# Montana register map
Vendor: ONSemiconductor; Series: Montana Series; File version: 1.0
CPU: CM33 r0p4, little endian, MPU, FPU, 3 interrupt priority bits
Registers are 32-bit, read-write, reset 0x0 unless marked. A register's access mark holds for its fields unless they carry their own. Offsets are from the block's base; [hi:lo] are bit positions; {n}, {i} and the like mark numbered series.

## SENSOR — Sensor domain (Analog Bridge Access)
Base 0x40001700
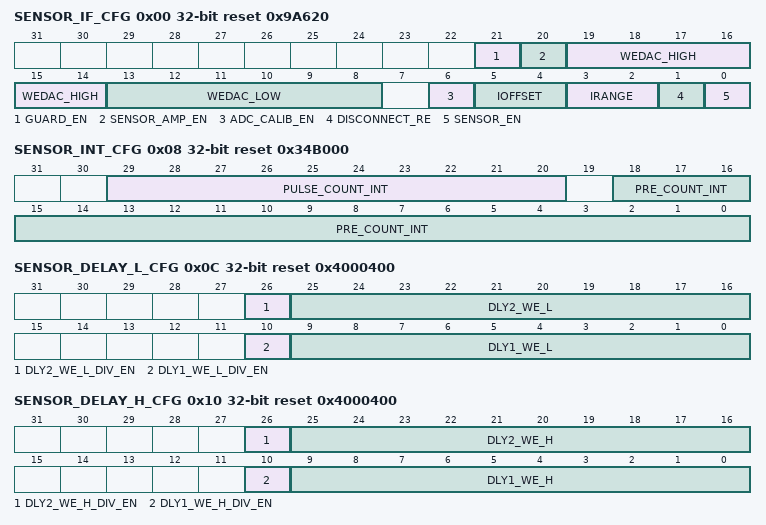
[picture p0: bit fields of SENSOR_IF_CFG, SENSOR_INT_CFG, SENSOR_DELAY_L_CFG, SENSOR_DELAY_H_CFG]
0x00 SENSOR_IF_CFG reset 0x9A620 — Sensor ADC configuration register
  [21] GUARD_EN — Guard buffer enable
    0=SENSOR_GUARD_DISABLED (Guard buffer disabled); 1=SENSOR_GUARD_ENABLED (Guard buffer enabled)
  [20] SENSOR_AMP_EN — Sensor amplifier enable
    0=SENSOR_AMP_DISABLED (Sensor amplifier disabled); 1=SENSOR_AMP_ENABLED (Sensor amplifier enabled)
  [19:14] WEDAC_HIGH — WEDAC output voltage during WE pulse
    0=SENSOR_WEDAC_HIGH_0000 (WEDAC_HIGH = 0.000V); 1=SENSOR_WEDAC_HIGH_0016 (WEDAC_HIGH = 0.016V); 2=SENSOR_WEDAC_HIGH_0032 (WEDAC_HIGH = 0.032V); 31=SENSOR_WEDAC_HIGH_0496 (WEDAC_HIGH = 0.496V); 32=SENSOR_WEDAC_HIGH_0504 (WEDAC_HIGH = 0.504V); 38=SENSOR_WEDAC_HIGH_0600 (WEDAC_HIGH = 0.600V); 39=SENSOR_WEDAC_HIGH_0616 (WEDAC_HIGH = 0.616V); 62=SENSOR_WEDAC_HIGH_0984 (WEDAC_HIGH = 0.984V); 63=SENSOR_WEDAC_HIGH_1000 (WEDAC_HIGH = 1.000V)
  [13:8] WEDAC_LOW — WEDAC output voltage except during WE pulse
    0=SENSOR_WEDAC_LOW_0000 (WEDAC_LOW = 0.000V); 1=SENSOR_WEDAC_LOW_0016 (WEDAC_LOW = 0.016V); 2=SENSOR_WEDAC_LOW_0032 (WEDAC_LOW = 0.032V); 31=SENSOR_WEDAC_LOW_0496 (WEDAC_LOW = 0.496V); 32=SENSOR_WEDAC_LOW_0504 (WEDAC_LOW = 0.504V); 38=SENSOR_WEDAC_LOW_0600 (WEDAC_LOW = 0.600V); 39=SENSOR_WEDAC_LOW_0616 (WEDAC_LOW = 0.616V); 62=SENSOR_WEDAC_LOW_0984 (WEDAC_LOW = 0.984V); 63=SENSOR_WEDAC_LOW_1000 (WEDAC_LOW = 1.000V)
  [6] ADC_CALIB_EN — ADC calibration mode enable (switches S2 & S3)
    0=SENSOR_CALIB_DISABLED (ADC calibration disabled); 1=SENSOR_CALIB_ENABLED (ADC calibration enabled)
  [5:4] IOFFSET — Sensor interface offset current setting
    0=SENSOR_IOFFSET_0NA (0 nA); 1=SENSOR_IOFFSET_10NA (10 nA); 2=SENSOR_IOFFSET_20NA (20 nA); 3=SENSOR_IOFFSET_40NA (40 nA)
  [3:2] IRANGE — Sensor interface measurement range
    0=SENSOR_IRANGE_50NA (50 nA); 1=SENSOR_IRANGE_80NA (80 nA); 2=SENSOR_IRANGE_170NA (170 nA); 3=SENSOR_IRANGE_240NA (240 nA)
  [1] DISCONNECT_RE — RE ground switch control (switch S1)
    0=SENSOR_RE_VSSA (RE shorted to VSSA); 1=SENSOR_RE_HIGHZ (RE high-Z)
  [0] SENSOR_EN — Sensor interface enable
    0=SENSOR_DISABLED (Sensor interface disabled); 1=SENSOR_ENABLED (Sensor interface enabled)
0x04 SENSOR_CLK_CFG — Sensor clock configuration register
  [0] CLK_SEL — Clock source selection
    0=SENSOR_CLK_RTC (RTC timer clock is used as sensor clock); 1=SENSOR_CLK_SLOWCLK (Divided SLOWCLK is used as sensor clock)
0x08 SENSOR_INT_CFG reset 0x34B000 — Sensor Integration Time Values
  [29:20] PULSE_COUNT_INT — Duration of "Pulse Count Sample" state
    {v}=Number of periods for "Pulse Count Sample State": {v+1} (v=0..3); 255=Number of periods for "Pulse Count Sample State": 256; 0x3FF=Number of periods for "Pulse Count Sample State": 1024
  [18:0] PRE_COUNT_INT — Absolute Value of main counter to trigger the change of "Pre Count Sample" state
    0=Number of periods for "Pre Count Int State": 1; 1=Number of periods for "Pre Count Int State": 2; 0x4AFFF=Number of periods for "Pre Count Int State": 307199; 0x4B000=Number of periods for "Pre Count Int State": 307200; 0x7FFFF=Number of periods for "Pre Count Int State": 2**19
0x0C SENSOR_DELAY_L_CFG reset 0x4000400 — Sensor Delays Time Values for Low states
  [26] DLY2_WE_L_DIV_EN
    0=DLY2_WE_L_DIV_DISABLED (Delay 2 WE_L runs at 32 kHz); 1=DLY2_WE_L_DIV_ENABLED (Delay 2 WE_L runs at 1 kHz)
  [25:16] DLY2_WE_L — Absolute Value of main counter to trigger the change of "Delay 2 WE_L" state
    0=Number of periods for "Delay 2 WE_L": 1; 1=Number of periods for "Delay 2 WE_L": 2; 255=Number of periods for "Delay 2 WE_L": 256; 0x3FF=Number of periods for "Delay 2 WE_L": 1024
  [10] DLY1_WE_L_DIV_EN
    0=DLY1_WE_L_DIV_DISABLED (Delay 1 WE_L runs at 32 kHz); 1=DLY1_WE_L_DIV_ENABLED (Delay 1 WE_L runs at 1 kHz)
  [9:0] DLY1_WE_L — Absolute Value of main counter to trigger the change of "Delay 1 WE_L" state
    0=Number of periods for "Delay 1 WE_L": 1; 1=Number of periods for "Delay 1 WE_L": 2; 255=Number of periods for "Delay 1 WE_L": 256; 0x3FF=Number of periods for "Delay 1 WE_L": 1024
0x10 SENSOR_DELAY_H_CFG reset 0x4000400 — Sensor Delays Time Values for High states
  [26] DLY2_WE_H_DIV_EN
    0=DLY2_WE_H_DIV_DISABLED (Delay 2 WE_H runs at 32 kHz); 1=DLY2_WE_H_DIV_ENABLED (Delay 2 WE_H runs at 1 kHz)
  [25:16] DLY2_WE_H — Absolute Value of main counter to trigger the change of "Delay 2 WE_H" state
    0=Number of periods for "Delay 2 WE_H": 1; 1=Number of periods for "Delay 2 WE_H": 2; 255=Number of periods for "Delay 2 WE_H": 256; 0x3FF=Number of periods for "Delay 2 WE_H": 1024
  [10] DLY1_WE_H_DIV_EN
    0=DLY1_WE_H_DIV_DISABLED (Delay 1 WE_H runs at 32 kHz); 1=DLY1_WE_H_DIV_ENABLED (Delay 1 WE_H runs at 1 kHz)
  [9:0] DLY1_WE_H — Absolute Value of main counter to trigger the change of "Delay 1 WE_H" state
    0=Number of periods for "Delay 1 WE_H": 1; 1=Number of periods for "Delay 1 WE_H": 2; 255=Number of periods for "Delay 1 WE_H": 256; 0x3FF=Number of periods for "Delay 1 WE_H": 1024
0x14 SENSOR_IDLE_CFG reset 0x4B000 — Sensor Idle Time Values
  [18:0] IDLE_TIME — Absolute Value of main counter to trigger the change of "Idle Time" state
    0=Number of periods for: 1; 1=Number of periods for: 2; 0x4B000=Number of periods for: 307200; 0x7FFFF=Number of periods for: 2**19
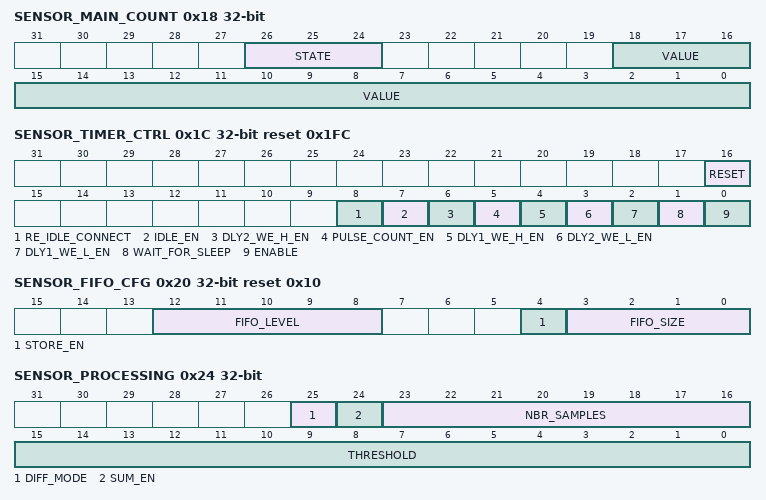
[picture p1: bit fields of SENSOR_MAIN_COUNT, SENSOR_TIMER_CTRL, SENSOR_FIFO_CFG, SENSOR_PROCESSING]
0x18 SENSOR_MAIN_COUNT ro — Sensor Main Counter Current Value
  [26:24] STATE — Sensor timer state
    0=DELAY_1_L_STATUS (Sensor Timer is on Delay 1 L state); 1=PRE_COUNT_STATUS (Sensor Timer is on Pre Count state); 2=DELAY_2_L_STATUS (Sensor Timer is on Delay 2 L state); 3=DELAY_1_H_STATUS (Sensor Timer is on Delay 1 H state); 4=PULSE_COUNT_STATUS (Sensor Timer is on Pulse Count state); 5=DELAY_2_H_STATUS (Sensor Timer is on Delay 2 H state); 6=IDLE_STATUS (Sensor Timer is on Idle state)
  [18:0] VALUE — Sensor main counter current value
0x1C SENSOR_TIMER_CTRL reset 0x1FC (reset mask 0x1FF) — Sensor Timer Control Register
  [16] RESET wo — Reset the Sensor timer
    1=SENSOR_CNT_RESET (The sensor timer counter, the sensor timer enable and the ADC counter are reset)
  [8] RE_IDLE_CONNECT — During idle state connect or disconnect RE pad
    0=RE_DISCONNECTED (The RE pad is disconnected during idle state); 1=RE_CONNECTED (The RE pad is connected during idle state)
  [7] IDLE_EN — Idle state enable
    0=IDLE_NOT_USED (Idle state is not used); 1=IDLE_USED (Idle state is used)
  [6] DLY2_WE_H_EN — Delay 2 WE_H state enable
    0=DLY2_WE_H_NOT_USED (Delay 2 WE_H state is not used); 1=DLY2_WE_H_USED (Delay 2 WE_H state is used)
  [5] PULSE_COUNT_EN — Pulse count state enable
    0=PULSE_CNT_NOT_USED (Pulse count state is not used); 1=PULSE_CNT_USED (Pulse count state is used)
  [4] DLY1_WE_H_EN — Delay 1 WE_H state enable
    0=DLY1_WE_H_NOT_USED (Delay 1 WE_H state is not used); 1=DLY1_WE_H_USED (Delay 1 WE_H state is used)
  [3] DLY2_WE_L_EN — Delay 2 WE_L state enable
    0=DLY2_WE_L_NOT_USED (Delay 2 WE_L state is not used); 1=DLY2_WE_L_USED (Delay 2 WE_L state is used)
  [2] DLY1_WE_L_EN — Delay 1 WE_L state enable
    0=DLY1_WE_L_NOT_USED (Delay 1 WE_L state is not used); 1=DLY1_WE_L_USED (Delay 1 WE_L state is used)
  [1] WAIT_FOR_SLEEP — Stop the counter until ASIC is in SLEEP mode
    0=WAITSLEEP_DISABLED (The timer runs independent of the sytem power mode); 1=WAITSLEEP_ENABLED (The timer runs only during SLEEP power mode)
  [0] ENABLE — Enable timer
    0=SENSOR_TIMER_DISABLED (The timer is disabled); 1=SENSOR_TIMER_ENABLED (The timer is enabled)
0x20 SENSOR_FIFO_CFG reset 0x10 — Sensor ADC data FIFO configuration
  [12:8] FIFO_LEVEL ro — Number of samples stored in FIFO
    0=SENSOR_FIFO_EMPTY (FIFO data level is 0); 16=SENSOR_FIFO_FULL (FIFO data level is 16)
  [4] STORE_EN — Enable the storage of sample on the FIFO
    0=SENSOR_FIFO_STORE_DISABLED (Samples are not stored in the FIFO); 1=SENSOR_FIFO_STORE_ENABLED (Samples are stored in the FIFO)
  [3:0] FIFO_SIZE — Number of ADC samples stored before waking up the core
    0=SENSOR_FIFO_SIZE1 (FIFO size 1; core wakes up after first ADC data arrives); {v}=SENSOR_FIFO_SIZE{v+1} (FIFO size {v+1}) (v=1..15)
0x24 SENSOR_PROCESSING — Sensor ADC wakeup threshold
  [25] DIFF_MODE — Differential mode enable, this mode use difference value between a pair of samples
    0=SENSOR_DIFF_MODE_DISABLED (Differential mode is disable); 1=SENSOR_DIFF_MODE_ENABLED (Differential mode is enable)
  [24] SUM_EN — Summation enable
    0=SENSOR_SUMMATION_DISABLED (Summation is disable); 1=SENSOR_SUMMATION_ENABLED (Summation is enable)
  [23:16] NBR_SAMPLES — Number of samples used by Summation and Threshold mode
    0=SENSOR_NBR_SAMPLES_1 (1 sample or 1 pair used); 1=SENSOR_NBR_SAMPLES_2 (2 sample or 2 pair used); 255=SENSOR_NBR_SAMPLES_255 (256 sample or 256 pair used)
  [15:0] THRESHOLD — Sensor data threshold for wakeup
    0=SENSOR_THRESHOLD_DISABLED (Sensor threshold functionality is disabled); 1=SENSOR_THRESHOLD_1 (Increments counter if sample (LSBs) is >= 0x0001); 0xFFFF=SENSOR_THRESHOLD_65535 (Increments counter if sample (LSBs) is >= 0xFFFF)
{0x28+4i} SENSOR_ADC_DATA[{i}] (i=0..15) ro — Sensor ADC output data FIFO
  [23:0] ADC_DATA — Sensor ADC output data
